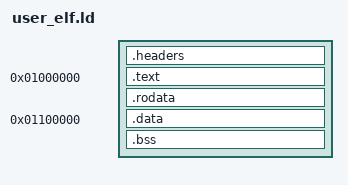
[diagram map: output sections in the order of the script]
OUTPUT_FORMAT(elf64-x86-64)
OUTPUT_ARCH(i386:x86-64)
ENTRY(_start)

PHDRS
{
    headers PT_LOAD FILEHDR PHDRS FLAGS(4);
    text PT_LOAD FLAGS(5);
    rodata PT_LOAD FLAGS(4);
    data PT_LOAD FLAGS(6);
}

SECTIONS
{
    . = 0x00fff000 + SIZEOF_HEADERS;
    .headers : {
        BYTE(0)
    } :headers

    . = 0x01000000;
    .text : ALIGN(4096) {
        *(.text .text.*)
    } :text

    . = ALIGN(4096);
    .rodata : {
        *(.rodata .rodata.*)
    } :rodata

    . = 0x01100000;
    .data : {
        *(.data .data.*)
    } :data
    .bss : {
        *(.bss .bss.*)
        *(COMMON)
    } :data

    /DISCARD/ : {
        *(.eh_frame .eh_frame.*)
        *(.note .note.*)
    }
}
